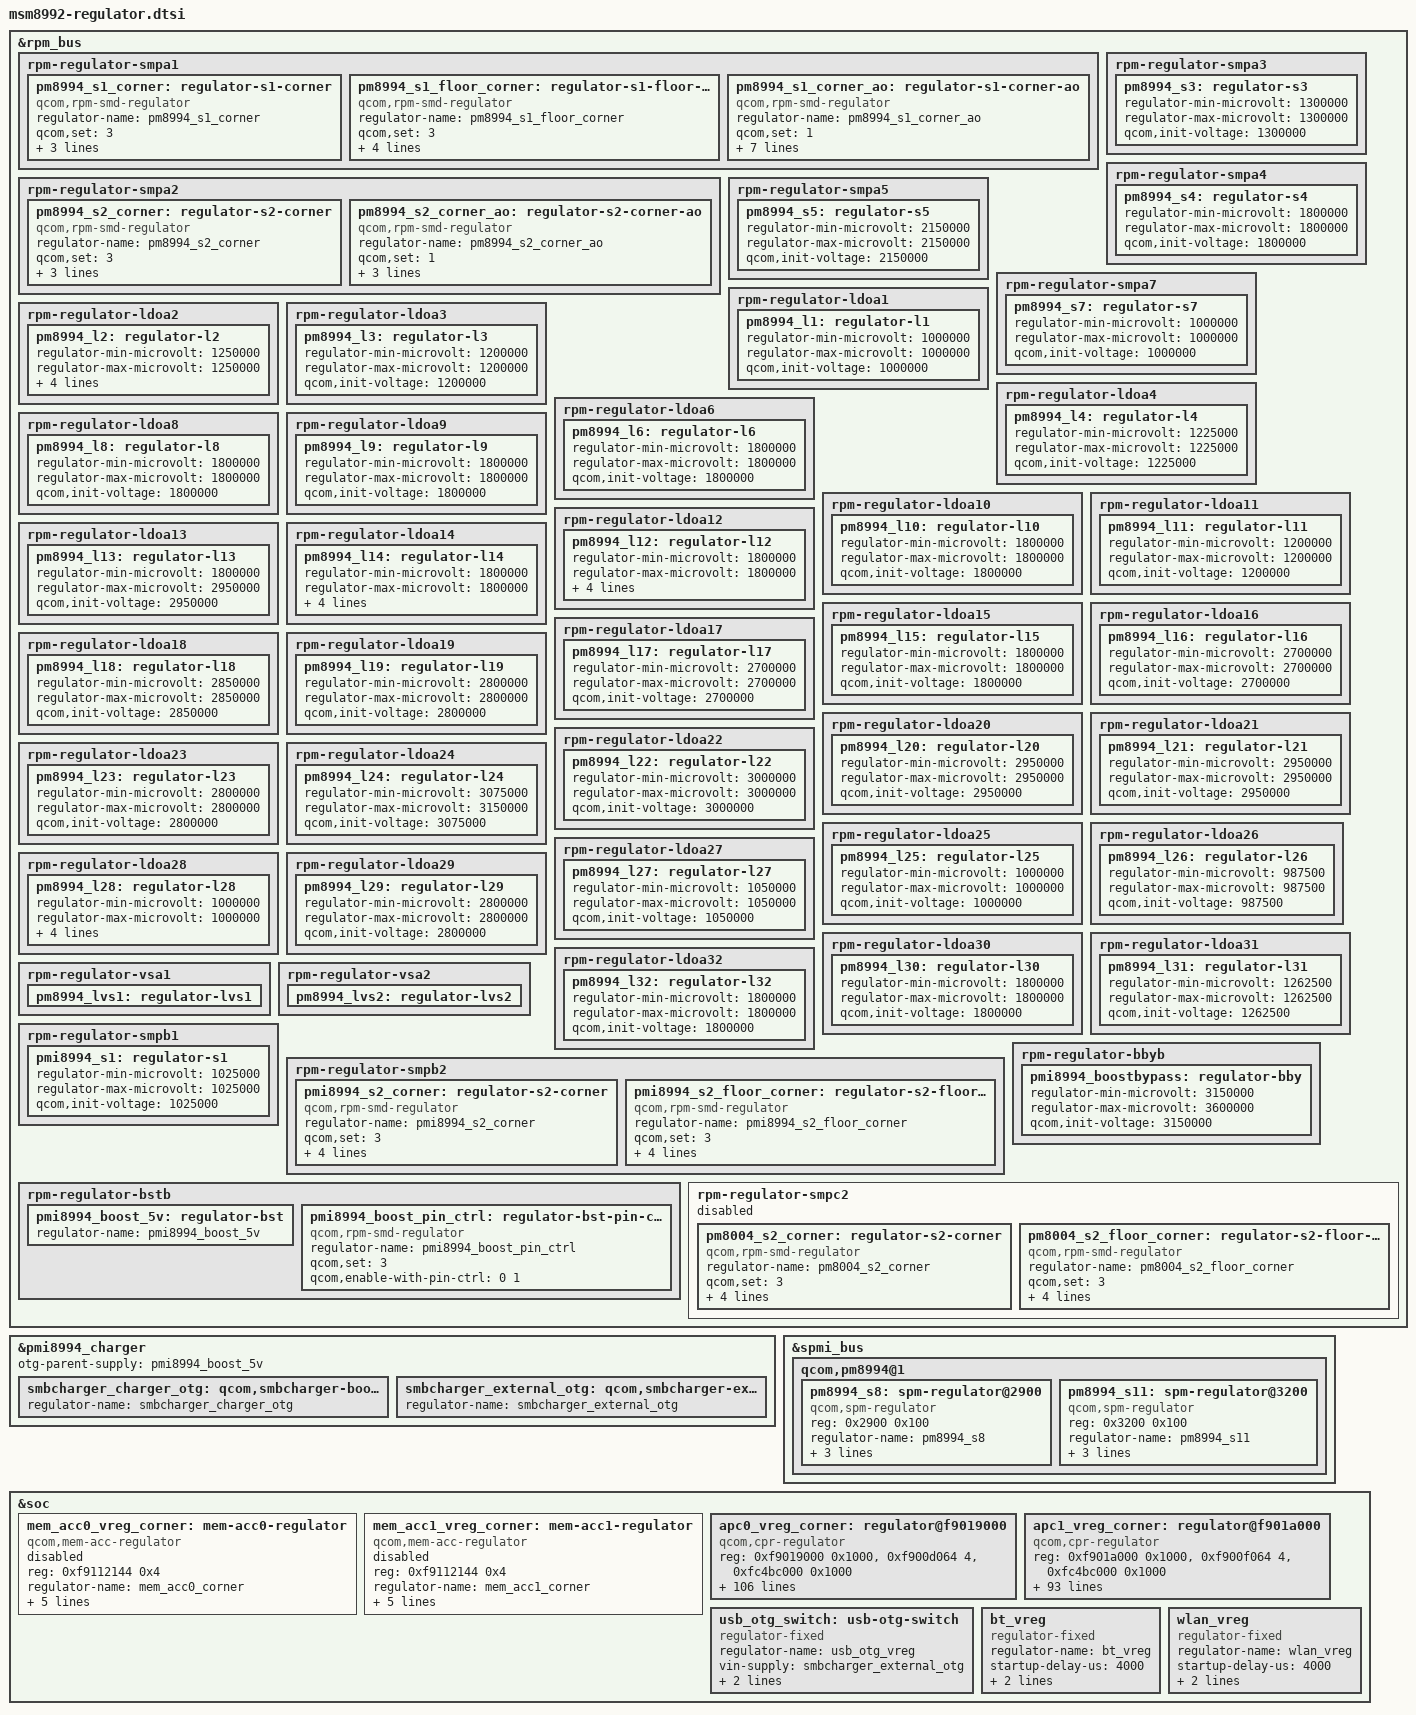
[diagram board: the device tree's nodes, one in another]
/* Copyright (c) 2014-2015, The Linux Foundation. All rights reserved.
 *
 * This program is free software; you can redistribute it and/or modify
 * it under the terms of the GNU General Public License version 2 and
 * only version 2 as published by the Free Software Foundation.
 *
 * This program is distributed in the hope that it will be useful,
 * but WITHOUT ANY WARRANTY; without even the implied warranty of
 * MERCHANTABILITY or FITNESS FOR A PARTICULAR PURPOSE.  See the
 * GNU General Public License for more details.
 */

&rpm_bus {
	/* PM8994 S1 + S6 = 2 phase VDD_CX supply */
	rpm-regulator-smpa1 {
		status = "okay";
		pm8994_s1_corner: regulator-s1-corner {
			compatible = "qcom,rpm-smd-regulator";
			regulator-name = "pm8994_s1_corner";
			qcom,set = <3>;
			regulator-min-microvolt = <1>;
			regulator-max-microvolt = <7>;
			qcom,use-voltage-corner;
		};

		pm8994_s1_floor_corner: regulator-s1-floor-corner {
			compatible = "qcom,rpm-smd-regulator";
			regulator-name = "pm8994_s1_floor_corner";
			qcom,set = <3>;
			regulator-min-microvolt = <1>;
			regulator-max-microvolt = <7>;
			qcom,use-voltage-floor-corner;
			qcom,always-send-voltage;
		};

		pm8994_s1_corner_ao: regulator-s1-corner-ao {
			compatible = "qcom,rpm-smd-regulator";
			regulator-name = "pm8994_s1_corner_ao";
			qcom,set = <1>;
			regulator-min-microvolt = <4>;
			regulator-max-microvolt = <7>;
			regulator-always-on;
			qcom,init-voltage-corner = <6>;
			qcom,use-voltage-corner;
			proxy-supply = <&pm8994_s1_corner_ao>;
			qcom,proxy-consumer-voltage = <7 7>;
		};
	};

	/* PM8994 S2 + S12 = 2 phase VDD_MX supply */
	rpm-regulator-smpa2 {
		status = "okay";
		pm8994_s2_corner: regulator-s2-corner {
			compatible = "qcom,rpm-smd-regulator";
			regulator-name = "pm8994_s2_corner";
			qcom,set = <3>;
			regulator-min-microvolt = <1>;
			regulator-max-microvolt = <7>;
			qcom,use-voltage-corner;
		};

		pm8994_s2_corner_ao: regulator-s2-corner-ao {
			compatible = "qcom,rpm-smd-regulator";
			regulator-name = "pm8994_s2_corner_ao";
			qcom,set = <1>;
			regulator-min-microvolt = <1>;
			regulator-max-microvolt = <7>;
			qcom,use-voltage-corner;
		};
	};

	rpm-regulator-smpa3 {
		status = "okay";
		pm8994_s3: regulator-s3 {
			regulator-min-microvolt = <1300000>;
			regulator-max-microvolt = <1300000>;
			qcom,init-voltage = <1300000>;
			status = "okay";
		};
	};

	rpm-regulator-smpa4 {
		status = "okay";
		pm8994_s4: regulator-s4 {
			regulator-min-microvolt = <1800000>;
			regulator-max-microvolt = <1800000>;
			qcom,init-voltage = <1800000>;
			status = "okay";
		};
	};

	rpm-regulator-smpa5 {
		status = "okay";
		pm8994_s5: regulator-s5 {
			regulator-min-microvolt = <2150000>;
			regulator-max-microvolt = <2150000>;
			qcom,init-voltage = <2150000>;
			status = "okay";
		};
	};

	rpm-regulator-smpa7 {
		status = "okay";
		pm8994_s7: regulator-s7 {
			regulator-min-microvolt = <1000000>;
			regulator-max-microvolt = <1000000>;
			qcom,init-voltage = <1000000>;
			status = "okay";
		};
	};

	rpm-regulator-ldoa1 {
		status = "okay";
		pm8994_l1: regulator-l1 {
			regulator-min-microvolt = <1000000>;
			regulator-max-microvolt = <1000000>;
			qcom,init-voltage = <1000000>;
			status = "okay";
		};
	};

	rpm-regulator-ldoa2 {
		status = "okay";
		pm8994_l2: regulator-l2 {
			regulator-min-microvolt = <1250000>;
			regulator-max-microvolt = <1250000>;
			qcom,init-voltage = <1250000>;
			proxy-supply = <&pm8994_l2>;
			qcom,proxy-consumer-enable;
			qcom,proxy-consumer-current = <10000>;
			status = "okay";
		};
	};

	rpm-regulator-ldoa3 {
		status = "okay";
		pm8994_l3: regulator-l3 {
			regulator-min-microvolt = <1200000>;
			regulator-max-microvolt = <1200000>;
			qcom,init-voltage = <1200000>;
			status = "okay";
		};
	};

	rpm-regulator-ldoa4 {
		status = "okay";
		pm8994_l4: regulator-l4 {
			regulator-min-microvolt = <1225000>;
			regulator-max-microvolt = <1225000>;
			qcom,init-voltage = <1225000>;
			status = "okay";
		};
	};

	rpm-regulator-ldoa6 {
		status = "okay";
		pm8994_l6: regulator-l6 {
			regulator-min-microvolt = <1800000>;
			regulator-max-microvolt = <1800000>;
			qcom,init-voltage = <1800000>;
			status = "okay";
		};
	};

	rpm-regulator-ldoa8 {
		status = "okay";
		pm8994_l8: regulator-l8 {
			regulator-min-microvolt = <1800000>;
			regulator-max-microvolt = <1800000>;
			qcom,init-voltage = <1800000>;
			status = "okay";
		};
	};

	rpm-regulator-ldoa9 {
		status = "okay";
		pm8994_l9: regulator-l9 {
			regulator-min-microvolt = <1800000>;
			regulator-max-microvolt = <1800000>;
			qcom,init-voltage = <1800000>;
			status = "okay";
		};
	};

	rpm-regulator-ldoa10 {
		status = "okay";
		pm8994_l10: regulator-l10 {
			regulator-min-microvolt = <1800000>;
			regulator-max-microvolt = <1800000>;
			qcom,init-voltage = <1800000>;
			status = "okay";
		};
	};

	rpm-regulator-ldoa11 {
		status = "okay";
		pm8994_l11: regulator-l11 {
			regulator-min-microvolt = <1200000>;
			regulator-max-microvolt = <1200000>;
			qcom,init-voltage = <1200000>;
			status = "okay";
		};
	};

	rpm-regulator-ldoa12 {
		status = "okay";
		pm8994_l12: regulator-l12 {
			regulator-min-microvolt = <1800000>;
			regulator-max-microvolt = <1800000>;
			qcom,init-voltage = <1800000>;
			proxy-supply = <&pm8994_l12>;
			qcom,proxy-consumer-enable;
			qcom,proxy-consumer-current = <10000>;
			status = "okay";
		};
	};

	rpm-regulator-ldoa13 {
		status = "okay";
		pm8994_l13: regulator-l13 {
			regulator-min-microvolt = <1800000>;
			regulator-max-microvolt = <2950000>;
			qcom,init-voltage = <2950000>;
			status = "okay";
		};
	};

	rpm-regulator-ldoa14 {
		status = "okay";
		pm8994_l14: regulator-l14 {
			regulator-min-microvolt = <1800000>;
			regulator-max-microvolt = <1800000>;
			qcom,init-voltage = <1800000>;
			proxy-supply = <&pm8994_l14>;
			qcom,proxy-consumer-enable;
			qcom,proxy-consumer-current = <10000>;
			status = "okay";
		};
	};

	rpm-regulator-ldoa15 {
		status = "okay";
		pm8994_l15: regulator-l15 {
			regulator-min-microvolt = <1800000>;
			regulator-max-microvolt = <1800000>;
			qcom,init-voltage = <1800000>;
			status = "okay";
		};
	};

	rpm-regulator-ldoa16 {
		status = "okay";
		pm8994_l16: regulator-l16 {
			regulator-min-microvolt = <2700000>;
			regulator-max-microvolt = <2700000>;
			qcom,init-voltage = <2700000>;
			status = "okay";
		};
	};

	rpm-regulator-ldoa17 {
		status = "okay";
		pm8994_l17: regulator-l17 {
			regulator-min-microvolt = <2700000>;
			regulator-max-microvolt = <2700000>;
			qcom,init-voltage = <2700000>;
			status = "okay";
		};
	};

	rpm-regulator-ldoa18 {
		status = "okay";
		pm8994_l18: regulator-l18 {
			regulator-min-microvolt = <2850000>;
			regulator-max-microvolt = <2850000>;
			qcom,init-voltage = <2850000>;
			status = "okay";
		};
	};

	rpm-regulator-ldoa19 {
		status = "okay";
		pm8994_l19: regulator-l19 {
			regulator-min-microvolt = <2800000>;
			regulator-max-microvolt = <2800000>;
			qcom,init-voltage = <2800000>;
			status = "okay";
		};
	};

	rpm-regulator-ldoa20 {
		status = "okay";
		pm8994_l20: regulator-l20 {
			regulator-min-microvolt = <2950000>;
			regulator-max-microvolt = <2950000>;
			qcom,init-voltage = <2950000>;
			status = "okay";
		};
	};

	rpm-regulator-ldoa21 {
		status = "okay";
		pm8994_l21: regulator-l21 {
			regulator-min-microvolt = <2950000>;
			regulator-max-microvolt = <2950000>;
			qcom,init-voltage = <2950000>;
			status = "okay";
		};
	};

	rpm-regulator-ldoa22 {
		status = "okay";
		pm8994_l22: regulator-l22 {
			regulator-min-microvolt = <3000000>;
			regulator-max-microvolt = <3000000>;
			qcom,init-voltage = <3000000>;
			status = "okay";
		};
	};

	rpm-regulator-ldoa23 {
		status = "okay";
		pm8994_l23: regulator-l23 {
			regulator-min-microvolt = <2800000>;
			regulator-max-microvolt = <2800000>;
			qcom,init-voltage = <2800000>;
			status = "okay";
		};
	};

	rpm-regulator-ldoa24 {
		status = "okay";
		pm8994_l24: regulator-l24 {
			regulator-min-microvolt = <3075000>;
			regulator-max-microvolt = <3150000>;
			qcom,init-voltage = <3075000>;
			status = "okay";
		};
	};

	rpm-regulator-ldoa25 {
		status = "okay";
		pm8994_l25: regulator-l25 {
			regulator-min-microvolt = <1000000>;
			regulator-max-microvolt = <1000000>;
			qcom,init-voltage = <1000000>;
			status = "okay";
		};
	};

	rpm-regulator-ldoa26 {
		status = "okay";
		pm8994_l26: regulator-l26 {
			regulator-min-microvolt = <987500>;
			regulator-max-microvolt = <987500>;
			qcom,init-voltage = <987500>;
			status = "okay";
		};
	};

	rpm-regulator-ldoa27 {
		status = "okay";
		pm8994_l27: regulator-l27 {
			regulator-min-microvolt = <1050000>;
			regulator-max-microvolt = <1050000>;
			qcom,init-voltage = <1050000>;
			status = "okay";
		};
	};

	rpm-regulator-ldoa28 {
		status = "okay";
		pm8994_l28: regulator-l28 {
			regulator-min-microvolt = <1000000>;
			regulator-max-microvolt = <1000000>;
			qcom,init-voltage = <1000000>;
			proxy-supply = <&pm8994_l28>;
			qcom,proxy-consumer-enable;
			qcom,proxy-consumer-current = <10000>;
			status = "okay";
		};
	};

	rpm-regulator-ldoa29 {
		status = "okay";
		pm8994_l29: regulator-l29 {
			regulator-min-microvolt = <2800000>;
			regulator-max-microvolt = <2800000>;
			qcom,init-voltage = <2800000>;
			status = "okay";
		};
	};

	rpm-regulator-ldoa30 {
		status = "okay";
		pm8994_l30: regulator-l30 {
			regulator-min-microvolt = <1800000>;
			regulator-max-microvolt = <1800000>;
			qcom,init-voltage = <1800000>;
			status = "okay";
		};
	};

	rpm-regulator-ldoa31 {
		status = "okay";
		pm8994_l31: regulator-l31 {
			regulator-min-microvolt = <1262500>;
			regulator-max-microvolt = <1262500>;
			qcom,init-voltage = <1262500>;
			status = "okay";
		};
	};

	rpm-regulator-ldoa32 {
		status = "okay";
		pm8994_l32: regulator-l32 {
			regulator-min-microvolt = <1800000>;
			regulator-max-microvolt = <1800000>;
			qcom,init-voltage = <1800000>;
			status = "okay";
		};
	};

	rpm-regulator-vsa1 {
		status = "okay";
		pm8994_lvs1: regulator-lvs1 {
			status = "okay";
		};
	};

	rpm-regulator-vsa2 {
		status = "okay";
		pm8994_lvs2: regulator-lvs2 {
			status = "okay";
		};
	};

	rpm-regulator-smpb1 {
		status = "okay";
		pmi8994_s1: regulator-s1 {
			regulator-min-microvolt = <1025000>;
			regulator-max-microvolt = <1025000>;
			qcom,init-voltage = <1025000>;
			status = "okay";
		};
	};

	/* PMI8994 S2 + S3 = 2 phase VDD_GFX supply */
	rpm-regulator-smpb2 {
		status = "okay";
		pmi8994_s2_corner: regulator-s2-corner {
			compatible = "qcom,rpm-smd-regulator";
			regulator-name = "pmi8994_s2_corner";
			qcom,set = <3>;
			qcom,init-voltage-corner = <2>; /* SVS SOC */
			regulator-min-microvolt = <1>;
			regulator-max-microvolt = <7>;
			qcom,use-voltage-corner;
		};

		pmi8994_s2_floor_corner: regulator-s2-floor-corner {
			compatible = "qcom,rpm-smd-regulator";
			regulator-name = "pmi8994_s2_floor_corner";
			qcom,set = <3>;
			regulator-min-microvolt = <1>;
			regulator-max-microvolt = <7>;
			qcom,use-voltage-floor-corner;
			qcom,always-send-voltage;
		};
	};

	rpm-regulator-bstb {
		status = "okay";
		pmi8994_boost_5v: regulator-bst {
			/*
			 * When enabled, the PMI8994 Boost regulator always
			 * outputs 5V.  This takes precedence over the pin
			 * control boost regulator request.
			 */
			regulator-name = "pmi8994_boost_5v";
			status = "okay";
		};
		pmi8994_boost_pin_ctrl: regulator-bst-pin-ctrl {
			/*
			 * When enabled, the output voltage of the PMI8994
			 * boost regulator is determined by the state of the
			 * REQ_5V_BST pin.  If the pin signal is high, then the
			 * regulator outputs 5V.  If the pin signal is low, then
			 * the regulator outputs VPH_PWR voltage.
			 */
			compatible = "qcom,rpm-smd-regulator";
			regulator-name = "pmi8994_boost_pin_ctrl";
			qcom,set = <3>;
			qcom,enable-with-pin-ctrl = <0 1>;
		};
	};

	rpm-regulator-bbyb {
		status = "okay";
		pmi8994_boostbypass: regulator-bby {
			status = "okay";
			regulator-min-microvolt = <3150000>;
			regulator-max-microvolt = <3600000>;
			qcom,init-voltage = <3150000>;
		};
	};

	/* PM8004 S2 + S4 = 2 phase VDD_GFX supply */
	rpm-regulator-smpc2 {
		status = "disabled";
		pm8004_s2_corner: regulator-s2-corner {
			compatible = "qcom,rpm-smd-regulator";
			regulator-name = "pm8004_s2_corner";
			qcom,set = <3>;
			qcom,init-voltage-corner = <2>; /* SVS SOC */
			regulator-min-microvolt = <1>;
			regulator-max-microvolt = <7>;
			qcom,use-voltage-corner;
		};

		pm8004_s2_floor_corner: regulator-s2-floor-corner {
			compatible = "qcom,rpm-smd-regulator";
			regulator-name = "pm8004_s2_floor_corner";
			qcom,set = <3>;
			regulator-min-microvolt = <1>;
			regulator-max-microvolt = <7>;
			qcom,use-voltage-floor-corner;
			qcom,always-send-voltage;
		};
	};
};

&pmi8994_charger {
	otg-parent-supply = <&pmi8994_boost_5v>;
	smbcharger_charger_otg: qcom,smbcharger-boost-otg {
		regulator-name = "smbcharger_charger_otg";
	};

	smbcharger_external_otg: qcom,smbcharger-external-otg {
		regulator-name = "smbcharger_external_otg";
	};
};

/* SPM controlled regulators: */
&spmi_bus {
	qcom,pm8994@1 {
		/* PM8994 S8 = VDD_APC0 supply */
		pm8994_s8: spm-regulator@2900 {
			compatible = "qcom,spm-regulator";
			reg = <0x2900 0x100>;
			regulator-name = "pm8994_s8";
			regulator-min-microvolt = <700000>;
			regulator-max-microvolt = <1180000>;
			qcom,cpu-num = <0>;
		};

		/*
		 * PM8994 S9 + S10 + S11 = 3 phase VDD_APC1 supply
		 * S11 is the gang leader.
		 */
		pm8994_s11: spm-regulator@3200 {
			compatible = "qcom,spm-regulator";
			reg = <0x3200 0x100>;
			regulator-name = "pm8994_s11";
			regulator-min-microvolt = <700000>;
			regulator-max-microvolt = <1225000>;
			qcom,cpu-num = <4>;
		};
	};
};

&soc {
/* CPR controlled regulators */
	mem_acc0_vreg_corner: mem-acc0-regulator {
		compatible = "qcom,mem-acc-regulator";
		reg = <0xf9112144 0x4>;
		reg-names = "acc-sel-l1";
		regulator-name = "mem_acc0_corner";
		regulator-min-microvolt = <1>;
		regulator-max-microvolt = <4>;
		qcom,corner-acc-map = <1 1 0 0>;
		qcom,acc-sel-l1-bit-pos = <0>;
		qcom,acc-sel-l1-bit-size = <1>;
		status = "disabled";
	};

	mem_acc1_vreg_corner: mem-acc1-regulator {
		compatible = "qcom,mem-acc-regulator";
		reg = <0xf9112144 0x4>;
		reg-names = "acc-sel-l1";
		regulator-name = "mem_acc1_corner";
		regulator-min-microvolt = <1>;
		regulator-max-microvolt = <4>;
		qcom,corner-acc-map = <1 1 0 0>;
		qcom,acc-sel-l1-bit-pos = <1>;
		qcom,acc-sel-l1-bit-size = <1>;
		status = "disabled";
	};

	apc0_vreg_corner: regulator@f9019000 {
		compatible = "qcom,cpr-regulator";
		reg = <0xf9019000 0x1000>, <0xf900d064 4>, <0xfc4bc000 0x1000>;
		reg-names = "rbcpr", "rbcpr_clk", "efuse_addr";
		interrupts = <0 16 0>;
		regulator-name = "apc0_corner";
		qcom,cpr-fuse-corners = <4>;
		regulator-min-microvolt = <1>;
		regulator-max-microvolt = <10>;

		qcom,cpr-voltage-ceiling = <900000 900000 1000000 1180000>;
		qcom,cpr-voltage-floor =   <640000 700000  800000  850000>;
		vdd-apc-supply = <&pm8994_s8>;

		qcom,vdd-mx-corner-map = <3 4 5 7>;
		qcom,vdd-mx-vmax = <7>;
		qcom,vdd-mx-vmin-method = <4>;
		vdd-mx-supply = <&pm8994_s2_corner_ao>;

		qcom,cpr-ref-clk = <19200>;
		qcom,cpr-timer-delay = <5000>;
		qcom,cpr-timer-cons-up = <0>;
		qcom,cpr-timer-cons-down = <2>;
		qcom,cpr-irq-line = <0>;
		qcom,cpr-step-quotient = <12>;
		qcom,cpr-up-threshold = <2>;
		qcom,cpr-down-threshold = <4>;
		qcom,cpr-idle-clocks = <15>;
		qcom,cpr-gcnt-time = <1>;
		qcom,vdd-apc-step-up-limit = <1>;
		qcom,vdd-apc-step-down-limit = <1>;
		qcom,cpr-apc-volt-step = <5000>;

		qcom,cpr-fuse-row = <138 0>;
		qcom,cpr-fuse-target-quot = <79 71 63 87>;
		qcom,cpr-fuse-target-quot-size = <8 8 8 8>;
		qcom,cpr-fuse-target-quot-scale =
					<0 10>,
					<0 10>,
					<0 10>,
					<0 10>;
		qcom,cpr-fuse-ro-sel = <98 98 95 101>;
		qcom,cpr-fuse-init-voltage =
					<139 46 6 0>,
					<139 46 6 0>,
					<139 40 6 0>,
					<139 52 6 0>;
		qcom,cpr-fuse-quot-offset =
					<27 50 6 0>,
					<27 50 6 0>,
					<138 48 6 0>,
					<138 54 7 0>;
		qcom,cpr-fuse-quot-offset-scale = <10 10 10 10>;
		qcom,cpr-fuse-revision = <137 34 3 0>;
		qcom,speed-bin-fuse-sel = <22 56 2 0>;

		qcom,fuse-remap-base-row = <1000>;
		qcom,fuse-remap-source =
					<56 21 41 0>,
					<136 62 12 0>;
		qcom,cpr-fuse-redun-sel = <62 48 3 1 0>;
		qcom,cpr-fuse-redun-row = <1000 0>;
		qcom,cpr-fuse-redun-target-quot = <0 8 16 24>;
		qcom,cpr-fuse-redun-ro-sel = <38 38 38 38>;
		qcom,cpr-fuse-redun-init-voltage =
					<1000 41 6 0>,
					<1000 41 6 0>,
					<1000 47 6 0>,
					<1000 32 6 0>;

		qcom,cpr-init-voltage-ref = <900000 900000 1000000 1230000>;
		qcom,cpr-init-voltage-step = <10000>;

		qcom,cpr-corner-map = <1 1 2 2 3 3 4 4 4 4>;
		qcom,cpr-voltage-ceiling-override =
				<0xFFFFFFFF 0  800000  800000  900000  900000
					      1000000 1000000 1115000 1115000
					      1180000 1180000>;
		qcom,cpr-voltage-floor-override =
				<0xFFFFFFFF 0  640000  655000  700000  735000
					       800000  835000  850000  875000
					       950000 1000000>;
		qcom,cpr-fuse-version-map =
				<0 0xffffffff 0 0 0 0 0>,
				<0 0xffffffff 1 0 0 0 0>,
				<0 0xffffffff 2 0 0 0 0>,
				<0 0xffffffff 3 0 0 0 0>,
				<0 0xffffffff 4 0 0 0 0>,
				<1 0xffffffff 0 0 0 0 0>,
				<1 0xffffffff 1 0 0 0 0>,
				<1 0xffffffff 2 0 0 0 0>,
				<1 0xffffffff 3 0 0 0 0>,
				<1 0xffffffff 4 0 0 0 0>;
		qcom,cpr-quotient-adjustment =
				<0 0 0 0>,
				<0 0 0 0>,
				<20 (-60) (-90) 20>,
				<(-70) (-100) (-100) (-10)>,
				<(-70) (-100) (-100) (-120)>,
				<0 0 0 0>,
				<0 0 0 0>,
				<20 (-60) (-90) 140>,
				<(-70) (-100) (-100) 110>,
				<(-70) (-100) (-100) 0>;
		qcom,cpr-quot-offset-adjustment =
				<0 0 0 0>,
				<0 0 0 0>,
				<0 (-80) (-30) 110>,
				<0 (-30) 0 90>,
				<0 (-30) 0 (-20)>,
				<0 0 0 0>,
				<0 0 0 0>,
				<0 (-80) (-30) 230>,
				<0 (-30) 0 210>,
				<0 (-30) 0 100>;
		qcom,cpr-fuse-min-quot-diff = <0 0 0 0>;
		qcom,cpr-min-quot-diff-adjustment =
					<0 0 0 0>,
					<0 0 0 0>,
					<0 0 0 0>,
					<0 0 0 0>,
					<0 0 0 0>,
					<0 0 0 0>,
					<0 0 0 0>,
					<0 0 0 0>,
					<0 0 0 0>,
					<0 0 0 0>;
		qcom,cpr-init-voltage-adjustment =
				<0 0 0 0>,
				<0 (-15000) (-35000) 35000>,
				<0 (-15000) (-35000) 35000>,
				<0 (-15000) (-25000) (-15000)>,
				<0 (-15000) (-25000) (-60000)>,
				<0 0 0 0>,
				<0 (-15000) (-35000) 95000>,
				<0 (-15000) (-35000) 95000>,
				<0 (-15000) (-25000) 45000>,
				<0 (-15000) (-25000) 0>;
		qcom,cpr-allowed =
				<0>,
				<0>,
				<1>,
				<1>,
				<1>,
				<0>,
				<0>,
				<1>,
				<1>,
				<1>;

		qcom,cpr-scaled-init-voltage-as-ceiling;
		qcom,cpr-voltage-scaling-factor-max = <0 0 2000 2000>;
		qcom,cpr-quot-adjust-scaling-factor-max = <0 2000 2000 2000>;
		qcom,cpr-corner-frequency-map =
				<1   300000000>,
				<2   384000000>,
				<3   460800000>,
				<4   600000000>,
				<5   672000000>,
				<6   787200000>,
				<7   864000000>,
				<8   960000000>,
				<9  1248000000>,
				<10 1440000000>;
		qcom,cpr-speed-bin-max-corners =
				<0 0 2 4 6 9>,
				<1 0 2 4 6 10>;
		qcom,cpr-enable;
	};

	apc1_vreg_corner: regulator@f901a000 {
		compatible = "qcom,cpr-regulator";
		reg = <0xf901a000 0x1000>, <0xf900f064 4>, <0xfc4bc000 0x1000>;
		reg-names = "rbcpr", "rbcpr_clk", "efuse_addr";
		interrupts = <0 19 0>;
		regulator-name = "apc1_corner";
		qcom,cpr-fuse-corners = <4>;
		regulator-min-microvolt = <1>;
		regulator-max-microvolt = <15>;

		qcom,cpr-voltage-ceiling = <900000 900000 1000000 1180000>;
		qcom,cpr-voltage-floor =   <640000 640000  745000  850000>;
		vdd-apc-supply = <&pm8994_s11>;

		qcom,vdd-mx-corner-map = <3 4 5 7>;
		qcom,vdd-mx-vmax = <7>;
		qcom,vdd-mx-vmin-method = <4>;
		vdd-mx-supply = <&pm8994_s2_corner_ao>;

		qcom,cpr-ref-clk = <19200>;
		qcom,cpr-timer-delay = <5000>;
		qcom,cpr-timer-cons-up = <0>;
		qcom,cpr-timer-cons-down = <2>;
		qcom,cpr-irq-line = <0>;
		qcom,cpr-step-quotient = <12>;
		qcom,cpr-up-threshold = <2>;
		qcom,cpr-down-threshold = <4>;
		qcom,cpr-idle-clocks = <15>;
		qcom,cpr-gcnt-time = <1>;
		qcom,cpr-clamp-timer-interval = <1>;
		qcom,vdd-apc-step-up-limit = <1>;
		qcom,vdd-apc-step-down-limit = <1>;
		qcom,cpr-apc-volt-step = <5000>;

		qcom,cpr-fuse-row = <140 0>;
		qcom,cpr-fuse-target-quot = <17 17 9 25>;
		qcom,cpr-fuse-target-quot-size = <8 8 8 8>;
		qcom,cpr-fuse-target-quot-scale =
					<0 10>,
					<0 10>,
					<0 10>,
					<0 10>;
		qcom,cpr-fuse-ro-sel = <36 36 33 39>;
		qcom,cpr-fuse-init-voltage =
					<140 48 6 0>,
					<140 48 6 0>,
					<140 42 6 0>,
					<140 54 6 0>;
		qcom,cpr-fuse-quot-offset =
					<27 56 6 0>,
					<27 56 6 0>,
					<139 58 6 0>,
					<140 0 7 0>;
		qcom,cpr-fuse-quot-offset-scale = <10 10 10 10>;
		qcom,cpr-fuse-revision = <137 34 3 0>;
		qcom,speed-bin-fuse-sel = <22 0 3 0>;

		qcom,fuse-remap-base-row = <1000>;
		qcom,fuse-remap-source =
					<56 62 2 0>,
					<57 55 9 0>,
					<136 0 22 0>,
					<137 10 12 0>;
		qcom,cpr-fuse-redun-sel = <62 48 3 1 0>;
		qcom,cpr-fuse-redun-row = <1000 0>;
		qcom,cpr-fuse-redun-target-quot = <0 0 8 16>;
		qcom,cpr-fuse-redun-ro-sel = <30 30 30 30>;
		qcom,cpr-fuse-redun-init-voltage =
					<1000 33 6 0>,
					<1000 33 6 0>,
					<1000 39 6 0>,
					<1000 24 6 0>;

		qcom,cpr-init-voltage-ref = <900000 900000 1000000 1230000>;
		qcom,cpr-init-voltage-step = <10000>;

		qcom,cpr-corner-map = <1 2 2 2 2 3 3 3 4 4 4 4 4 4 4>;
		qcom,cpr-voltage-ceiling-override =
				<0xFFFFFFFF 0  900000  900000  900000  900000
					       900000 1000000 1000000 1000000
					      1115000 1115000 1115000 1115000
					      1115000 1115000 1180000>;
		qcom,cpr-voltage-floor-override =
				<0xFFFFFFFF 0  640000  640000  665000  690000
					       735000  745000  770000  785000
					       850000  860000  880000  900000
					       920000  935000 1000000>;
		qcom,cpr-fuse-version-map =
				<0xffffffff 0xffffffff 0 4 4 4 4>,
				<0xffffffff 0xffffffff 1 4 4 4 4>,
				<0xffffffff 0xffffffff 2 4 4 4 4>,
				<0xffffffff 0xffffffff 3 2 2 2 2>,
				<0xffffffff 0xffffffff 4 2 2 2 2>;
		qcom,cpr-quotient-adjustment =
				<0 0 0 0>,
				<0 0 0 0>,
				<(-21) (-21) 21 (-42)>,
				<12 12 (-84) (-24)>,
				<12 12 (-84) (-24)>;
		qcom,cpr-quot-offset-adjustment =
				<0 0 0 0>,
				<0 0 0 0>,
				<0 0 42 (-63)>,
				<0 0 (-96) 60>,
				<0 0 (-96) 60>;
		qcom,cpr-fuse-min-quot-diff = <0 0 0 0>;
		qcom,cpr-min-quot-diff-adjustment =
					<0 0 0 0>,
					<0 0 0 0>,
					<0 0 0 0>,
					<0 0 0 0>,
					<0 0 0 0>;
		qcom,cpr-init-voltage-adjustment =
				<0 0 0 0>,
				<0 0 (-25000) (-25000)>,
				<0 0 30000 (-5000)>,
				<30000 30000 (-20000) (-20000)>,
				<30000 30000 (-20000) (-20000)>;
		qcom,cpr-allowed =
				<0>,
				<0>,
				<1>,
				<1>,
				<1>;

		qcom,cpr-scaled-init-voltage-as-ceiling;
		qcom,cpr-voltage-scaling-factor-max = <0 0 2000 2000>;
		qcom,cpr-quot-adjust-scaling-factor-max = <0 0 2000 2000>;
		qcom,cpr-corner-frequency-map =
				<1   300000000>, /* SVS Fmin for "SVS2" */
				<2   300000000>,
				<3   384000000>,
				<4   480000000>,
				<5   633600000>,
				<6   768000000>,
				<7   864000000>,
				<8   960000000>,
				<9  1248000000>,
				<10 1344000000>,
				<11 1440000000>,
				<12 1536000000>,
				<13 1632000000>,
				<14 1689600000>,
				<15 1824000000>;
		qcom,cpr-speed-bin-max-corners =
				<0xFFFFFFFF 0 1 5 8 15>;
		qcom,cpr-enable;
	};

/* Miscellaneous regulators */
	usb_otg_switch: usb-otg-switch {
		compatible = "regulator-fixed";
		regulator-name = "usb_otg_vreg";
		vin-supply = <&smbcharger_external_otg>;
		enable-active-high;
		gpio = <&pmi8994_gpios 5 0>;
	};

	bt_vreg: bt_vreg {
		compatible = "regulator-fixed";
		regulator-name = "bt_vreg";
		startup-delay-us = <4000>;
		enable-active-high;
		gpio = <&pm8994_gpios 9 0>;
	};

	wlan_vreg: wlan_vreg {
		compatible = "regulator-fixed";
		regulator-name = "wlan_vreg";
		startup-delay-us = <4000>;
		enable-active-high;
		gpio = <&pm8994_gpios 9 0>;
	};
};
